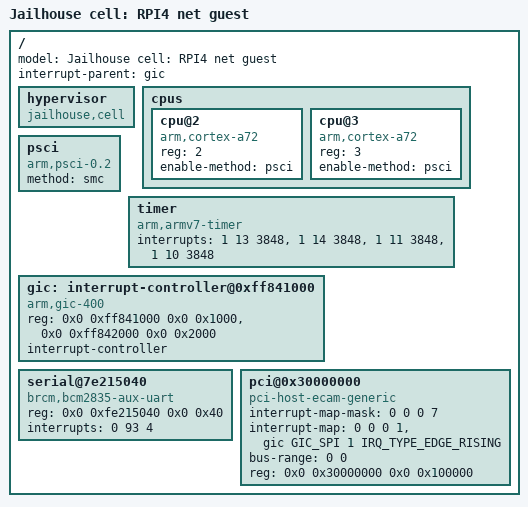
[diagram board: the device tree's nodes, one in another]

#include <dt-bindings/interrupt-controller/arm-gic.h>

/dts-v1/;

/ {
	model = "Jailhouse cell: RPI4 net guest";

	#address-cells = <2>;
	#size-cells = <2>;

	interrupt-parent = < &gic>;

	hypervisor {
		compatible = "jailhouse,cell";
	};

	cpus {
		#address-cells = <1>;
		#size-cells = <0>;
		cpu@2 {
			device_type = "cpu";
			compatible = "arm,cortex-a72";
			reg = <2>;
			enable-method = "psci";
		};
		cpu@3 {
			device_type = "cpu";
			compatible = "arm,cortex-a72";
			reg = <3>;
			enable-method = "psci";
		};
	};

	psci {
		compatible = "arm,psci-0.2";
		method = "smc";
	};
    
    timer {
        compatible = "arm,armv7-timer";
        interrupts = 
              <1 13 3848>,
              <1 14 3848>,
              <1 11 3848>,
              <1 10 3848>;

    };

	gic: interrupt-controller@0xff841000 {
		compatible = "arm,gic-400";
		reg = <0x0 0xff841000 0x0 0x1000>,
		      <0x0 0xff842000 0x0 0x2000>;
		interrupt-controller;
		#interrupt-cells = <3>;
	};


    serial@7e215040 {
        compatible = "brcm,bcm2835-aux-uart";
        reg = <0x0 0xfe215040 0x0 0x40>;
        interrupts = <
                        0 93 4
                      >;
        status = "okay";
	};


    pci@0x30000000 {
        compatible = "pci-host-ecam-generic";
        device_type = "pci";
        #address-cells = <3>;
        #size-cells = <2>;
        #interrupt-cells = <1>;
        interrupt-map-mask = <0 0 0 7>;
        interrupt-map =  
            <0 0 0 1 &gic GIC_SPI 1 IRQ_TYPE_EDGE_RISING>;
        bus-range = <0 0>;
        reg = <0x0 0x30000000 0x0 0x100000>;
        ranges =
             <0x02000000 0x00 0x10000000 0x0 0x10000000 0x00 0x10000>;
	};
	
};
